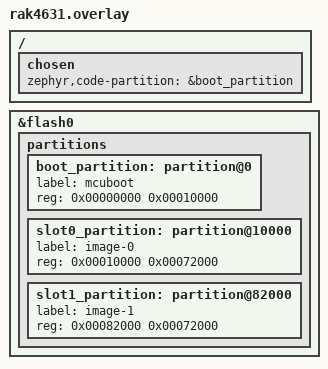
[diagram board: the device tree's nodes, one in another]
/*
 * SPDX-License-Identifier: Apache-2.0
 */

/ {
	chosen {
		zephyr,code-partition = &boot_partition;
	};
};

/delete-node/ &boot_partition;
/delete-node/ &slot0_partition;
/delete-node/ &slot1_partition;

&flash0 {
	partitions {
		boot_partition: partition@0 {
			label = "mcuboot";
			reg = <0x00000000 0x00010000>;
		};
		slot0_partition: partition@10000 {
			label = "image-0";
			reg = <0x00010000 0x00072000>;
		};
		slot1_partition: partition@82000 {
			label = "image-1";
			reg = <0x00082000 0x00072000>;
		};
	};
};
